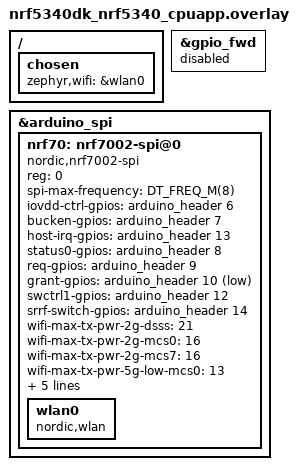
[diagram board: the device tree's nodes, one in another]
/*
 * Copyright (c) 2024 Nordic Semiconductor ASA
 *
 * SPDX-License-Identifier: Apache-2.0
 */
#include <freq.h>

/ {
	chosen {
		zephyr,wifi = &wlan0;
	};
};

&gpio_fwd {
	status = "disabled";
};

&arduino_spi {
	status = "okay";

	nrf70: nrf7002-spi@0 {
		compatible = "nordic,nrf7002-spi";
		status = "okay";
		reg = <0>;
		spi-max-frequency = <DT_FREQ_M(8)>;





		/* Include common nRF70 overlays */
		/*
		 * Copyright (c) 2024 Nordic Semiconductor ASA
		 *
		 * SPDX-License-Identifier: Apache-2.0
		 */

		/* Common assignments for any nRF70 shield */

		/* D0 */
		iovdd-ctrl-gpios = <&arduino_header 6 (GPIO_ACTIVE_HIGH | GPIO_PULL_DOWN)>;
		/* D1 */
		bucken-gpios = <&arduino_header 7 (GPIO_ACTIVE_HIGH | GPIO_PULL_DOWN)>;
		/* D7 */
		host-irq-gpios = <&arduino_header 13 GPIO_ACTIVE_HIGH>;
		/* Short-range (SR) co-existence */
		/* D2 */
		status0-gpios = <&arduino_header 8 GPIO_ACTIVE_HIGH>;
		/* D3 */
		req-gpios = <&arduino_header 9 GPIO_ACTIVE_HIGH>;
		/* D4 */
		grant-gpios = <&arduino_header 10 (GPIO_PULL_DOWN | GPIO_ACTIVE_LOW)>;
		/* D6 */
		swctrl1-gpios = <&arduino_header 12 GPIO_ACTIVE_HIGH>;
		/* D8 */
		srrf-switch-gpios = <&arduino_header 14 GPIO_ACTIVE_HIGH>;

		/* Maximum TX power limits for 2.4 GHz */
		wifi-max-tx-pwr-2g-dsss = <21>;
		wifi-max-tx-pwr-2g-mcs0 = <16>;
		wifi-max-tx-pwr-2g-mcs7 = <16>;

		/* List of interfaces */
		wlan0: wlan0 {
			compatible = "nordic,wlan";
		};



		/*
		 * Copyright (c) 2024 Nordic Semiconductor ASA
		 *
		 * SPDX-License-Identifier: Apache-2.0
		 */

		wifi-max-tx-pwr-5g-low-mcs0 = <13>;
		wifi-max-tx-pwr-5g-low-mcs7 = <13>;
		wifi-max-tx-pwr-5g-mid-mcs0 = <13>;
		wifi-max-tx-pwr-5g-mid-mcs7 = <13>;
		wifi-max-tx-pwr-5g-high-mcs0 = <12>;
		wifi-max-tx-pwr-5g-high-mcs7 = <12>;
	};
};
